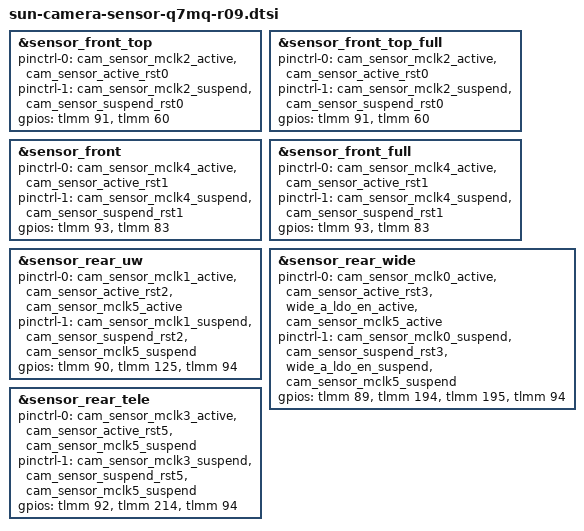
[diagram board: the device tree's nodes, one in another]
#include "sun-camera-sensor-q7mq-r02.dtsi"

&sensor_front_top{
	pinctrl-0 = <&cam_sensor_mclk2_active  &cam_sensor_active_rst0>;
	pinctrl-1=  <&cam_sensor_mclk2_suspend  &cam_sensor_suspend_rst0>;
	gpios= <&tlmm 91 0>, <&tlmm 60 0>;
};

&sensor_front_top_full{
	pinctrl-0 = <&cam_sensor_mclk2_active  &cam_sensor_active_rst0>;
	pinctrl-1=  <&cam_sensor_mclk2_suspend  &cam_sensor_suspend_rst0>;
	gpios= <&tlmm 91 0>, <&tlmm 60 0>;
};

&sensor_front{
	pinctrl-0 = <&cam_sensor_mclk4_active  &cam_sensor_active_rst1>;
	pinctrl-1=  <&cam_sensor_mclk4_suspend  &cam_sensor_suspend_rst1>;
	gpios= <&tlmm 93 0>, <&tlmm 83 0>;
};

&sensor_front_full{
	pinctrl-0 = <&cam_sensor_mclk4_active  &cam_sensor_active_rst1>;
	pinctrl-1=  <&cam_sensor_mclk4_suspend  &cam_sensor_suspend_rst1>;
	gpios= <&tlmm 93 0>, <&tlmm 83 0>;
};

&sensor_rear_uw{
	pinctrl-0 = <&cam_sensor_mclk1_active  &cam_sensor_active_rst2 &cam_sensor_mclk5_active>;
	pinctrl-1 =  <&cam_sensor_mclk1_suspend  &cam_sensor_suspend_rst2 &cam_sensor_mclk5_suspend>;
	gpios =  <&tlmm 90 0>, <&tlmm 125 0>, <&tlmm 94 0>;
};

&sensor_rear_wide{
	pinctrl-0 = <&cam_sensor_mclk0_active  &cam_sensor_active_rst3  &wide_a_ldo_en_active &cam_sensor_mclk5_active>;
	pinctrl-1 = <&cam_sensor_mclk0_suspend  &cam_sensor_suspend_rst3  &wide_a_ldo_en_suspend &cam_sensor_mclk5_suspend>;
	gpios = <&tlmm 89 0>, <&tlmm 194 0>, <&tlmm 195 0>, <&tlmm 94 0>;
};

&sensor_rear_tele{
	pinctrl-0 = <&cam_sensor_mclk3_active  &cam_sensor_active_rst5 &cam_sensor_mclk5_suspend>;
	pinctrl-1 = <&cam_sensor_mclk3_suspend  &cam_sensor_suspend_rst5 &cam_sensor_mclk5_suspend>;
	gpios = <&tlmm 92 0>, <&tlmm 214 0>, <&tlmm 94 0>;
};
